VERSION ""

NS_ :

BS_:

BU_: XXX CAMERA FRONT_RADAR ADRV APRK

BO_ 53 ACCELERATOR: 32 XXX
 SG_ CHECKSUM : 0|16@1+ (1,0) [0|65535] "" XXX
 SG_ COUNTER : 16|8@1+ (1,0) [0|255] "" XXX
 SG_ GEAR : 192|3@1+ (1,0) [0|7] "" XXX
 SG_ ACCELERATOR_PEDAL : 40|8@1+ (1,0) [0|255] "" XXX

BO_ 64 GEAR_ALT: 32 XXX
 SG_ CHECKSUM : 0|16@1+ (1,0) [0|65535] "" XXX
 SG_ COUNTER : 16|8@1+ (1,0) [0|255] "" XXX
 SG_ GEAR : 32|3@1+ (1,0) [0|7] "" XXX

BO_ 69 GEAR: 24 XXX
 SG_ CHECKSUM : 0|16@1+ (1,0) [0|65535] "" XXX
 SG_ COUNTER : 16|8@1+ (1,0) [0|255] "" XXX
 SG_ GEAR : 44|3@1+ (1,0) [0|7] "" XXX

BO_ 80 LKAS: 16 XXX
 SG_ STEER_REQ : 52|1@1+ (1,0) [0|1] "" XXX
 SG_ TORQUE_REQUEST : 41|11@1+ (1,-1024) [0|4095] "" XXX
 SG_ LKA_ICON : 38|2@1+ (1,0) [0|255] "" XXX
 SG_ NEW_SIGNAL_1 : 27|2@1+ (1,0) [0|255] "" XXX
 SG_ LFA_BUTTON : 56|1@1+ (1,0) [0|255] "" XXX
 SG_ COUNTER : 16|8@1+ (1,0) [0|255] "" XXX
 SG_ CHECKSUM : 0|16@1+ (1,0) [0|65535] "" XXX
 SG_ STEER_MODE : 65|3@1+ (1,0) [0|1] "" XXX
 SG_ LKA_WARNING : 32|1@1+ (1,0) [0|1] "" XXX
 SG_ LKA_ASSIST : 62|1@1+ (1,0) [0|1] "" XXX
 SG_ LKA_MODE : 24|3@1+ (1,0) [0|7] "" XXX
 SG_ NEW_SIGNAL_2 : 70|2@0+ (1,0) [0|3] "" XXX
 SG_ HAS_LANE_SAFETY : 80|1@0+ (1,0) [0|1] "" XXX
 SG_ NEW_SIGNAL_3 : 111|8@0+ (1,0) [0|255] "" XXX
 SG_ FCA_SYSWARN : 40|1@0+ (1,0) [0|1] "" XXX

BO_ 81 ADRV_0x51: 32 ADRV
 SG_ COUNTER : 16|8@1+ (1,0) [0|255] "" XXX
 SG_ CHECKSUM : 0|16@1+ (1,0) [0|65535] "" XXX

BO_ 96 ESP_STATUS: 32 XXX
 SG_ CHECKSUM : 0|16@1+ (1,0) [0|65535] "" XXX
 SG_ COUNTER : 16|8@1+ (1,0) [0|255] "" XXX
 SG_ TRACTION_AND_STABILITY_CONTROL : 42|3@1+ (1,0) [0|63] "" XXX
 SG_ BRAKE_PRESSURE : 128|10@1+ (1,0) [0|65535] "" XXX
 SG_ BRAKE_PRESSED : 148|1@1+ (1,0) [0|3] "" XXX
 SG_ AUTO_HOLD : 192|1@0+ (1,0) [0|1] "" XXX

BO_ 101 BRAKE: 32 XXX
 SG_ CHECKSUM : 0|16@1+ (1,0) [0|65535] "" XXX
 SG_ COUNTER : 16|8@1+ (1,0) [0|255] "" XXX
 SG_ BRAKE_LIGHT : 29|1@0+ (1,0) [0|1] "" XXX
 SG_ BRAKE_POSITION : 40|16@1- (1,0) [0|65535] "" XXX
 SG_ BRAKE_PRESSED : 57|1@1+ (1,0) [0|3] "" XXX

BO_ 112 GEAR_ALT_2: 32 XXX
 SG_ CHECKSUM : 0|16@1+ (1,0) [0|65535] "" XXX
 SG_ COUNTER : 16|8@1+ (1,0) [0|255] "" XXX
 SG_ GEAR : 60|3@1+ (1,0) [0|7] "" XXX

BO_ 160 WHEEL_SPEEDS: 24 XXX
 SG_ CHECKSUM : 0|16@1+ (1,0) [0|65535] "" XXX
 SG_ COUNTER : 16|8@1+ (1,0) [0|255] "" XXX
 SG_ MOVING_FORWARD : 56|1@0+ (1,0) [0|1] "" XXX
 SG_ MOVING_BACKWARD : 57|1@0+ (1,0) [0|1] "" XXX
 SG_ MOVING_FORWARD2 : 58|1@0+ (1,0) [0|1] "" XXX
 SG_ MOVING_BACKWARD2 : 59|1@0+ (1,0) [0|1] "" XXX
 SG_ WHEEL_SPEED_1 : 64|16@1+ (0.03125,0) [0|65535] "kph" XXX
 SG_ WHEEL_SPEED_2 : 80|16@1+ (0.03125,0) [0|65535] "kph" XXX
 SG_ WHEEL_SPEED_3 : 96|16@1+ (0.03125,0) [0|65535] "kph" XXX
 SG_ WHEEL_SPEED_4 : 112|16@1+ (0.03125,0) [0|65535] "kph" XXX

BO_ 234 MDPS: 24 XXX
 SG_ CHECKSUM : 0|16@1+ (1,0) [0|65535] "" XXX
 SG_ COUNTER : 16|8@1+ (1,0) [0|255] "" XXX
 SG_ LKA_ACTIVE : 48|1@0+ (1,0) [0|16777215] "" XXX
 SG_ LKA_FAULT : 54|1@0+ (1,0) [0|1] "" XXX
 SG_ STEERING_OUT_TORQUE : 64|12@1+ (0.1,-204.8) [0|65535] "" XXX
 SG_ STEERING_COL_TORQUE : 80|13@1+ (1,-4095) [0|4095] "" XXX
 SG_ STEERING_ANGLE : 96|16@1- (-0.1,0) [0|255] "deg" XXX
 SG_ STEERING_ANGLE_2 : 128|16@1- (-0.1,0) [0|65535] "deg" XXX

BO_ 256 ACCELERATOR_BRAKE_ALT: 32 XXX
 SG_ CHECKSUM : 0|16@1+ (1,0) [0|65535] "" XXX
 SG_ COUNTER : 16|8@1+ (1,0) [0|255] "" XXX
 SG_ BRAKE_PRESSED : 32|1@1+ (1,0) [0|1] "" XXX
 SG_ ACCELERATOR_PEDAL_PRESSED : 176|1@1+ (1,0) [0|1] "" XXX

BO_ 261 ACCELERATOR_ALT: 32 XXX
 SG_ CHECKSUM : 0|16@1+ (1,0) [0|65535] "" XXX
 SG_ COUNTER : 16|8@1+ (1,0) [0|255] "" XXX
 SG_ ACCELERATOR_PEDAL : 103|10@1+ (0.25,0) [0|1022] "" XXX

BO_ 272 LKAS_ALT: 32 XXX
 SG_ STEER_REQ : 52|1@1+ (1,0) [0|1] "" XXX
 SG_ TORQUE_REQUEST : 41|11@1+ (1,-1024) [0|4095] "" XXX
 SG_ LKA_ICON : 38|2@1+ (1,0) [0|255] "" XXX
 SG_ NEW_SIGNAL_1 : 27|2@1+ (1,0) [0|255] "" XXX
 SG_ LFA_BUTTON : 56|1@1+ (1,0) [0|255] "" XXX
 SG_ COUNTER : 16|8@1+ (1,0) [0|255] "" XXX
 SG_ CHECKSUM : 0|16@1+ (1,0) [0|65535] "" XXX
 SG_ STEER_MODE : 65|3@1+ (1,0) [0|1] "" XXX
 SG_ LKA_WARNING : 32|1@1+ (1,0) [0|1] "" XXX
 SG_ LKA_ASSIST : 62|1@1+ (1,0) [0|1] "" XXX
 SG_ LKA_MODE : 24|3@1+ (1,0) [0|7] "" XXX
 SG_ NEW_SIGNAL_2 : 70|2@0+ (1,0) [0|3] "" XXX
 SG_ HAS_LANE_SAFETY : 80|1@0+ (1,0) [0|1] "" XXX
 SG_ NEW_SIGNAL_3 : 111|8@0+ (1,0) [0|255] "" XXX
 SG_ FCA_SYSWARN : 40|1@0+ (1,0) [0|1] "" XXX

BO_ 293 STEERING_SENSORS: 16 XXX
 SG_ CHECKSUM : 0|16@1+ (1,0) [0|65535] "" XXX
 SG_ COUNTER : 16|8@1+ (1,0) [0|255] "" XXX
 SG_ STEERING_RATE : 40|8@1+ (4,0) [0|1016] "deg/s" XXX
 SG_ STEERING_ANGLE : 24|16@1- (-0.1,0) [0|255] "deg" XXX

BO_ 298 LFA: 16 ADRV
 SG_ STEER_REQ : 52|1@1+ (1,0) [0|1] "" XXX
 SG_ TORQUE_REQUEST : 41|11@1+ (1,-1024) [0|4095] "" XXX
 SG_ LKA_ICON : 38|2@1+ (1,0) [0|255] "" XXX
 SG_ NEW_SIGNAL_1 : 27|2@1+ (1,0) [0|255] "" XXX
 SG_ LFA_BUTTON : 56|1@1+ (1,0) [0|255] "" XXX
 SG_ COUNTER : 16|8@1+ (1,0) [0|255] "" XXX
 SG_ CHECKSUM : 0|16@1+ (1,0) [0|65535] "" XXX
 SG_ STEER_MODE : 65|3@1+ (1,0) [0|1] "" XXX
 SG_ LKA_WARNING : 32|1@1+ (1,0) [0|1] "" XXX
 SG_ LKA_ASSIST : 62|1@1+ (1,0) [0|1] "" XXX
 SG_ LKA_MODE : 24|3@1+ (1,0) [0|7] "" XXX
 SG_ NEW_SIGNAL_2 : 70|2@0+ (1,0) [0|3] "" XXX
 SG_ HAS_LANE_SAFETY : 80|1@0+ (1,0) [0|1] "" XXX
 SG_ NEW_SIGNAL_3 : 111|8@0+ (1,0) [0|255] "" XXX

BO_ 304 GEAR_SHIFTER: 16 XXX
 SG_ CHECKSUM : 0|16@1+ (1,0) [0|65535] "" XXX
 SG_ COUNTER : 16|8@1+ (1,0) [0|255] "" XXX
 SG_ PARK_BUTTON : 32|2@1+ (1,0) [0|3] "" XXX
 SG_ GEAR : 64|3@1+ (1,0) [0|7] "" XXX
 SG_ KNOB_POSITION : 40|3@1+ (1,0) [0|3] "" XXX

BO_ 357 SPAS1: 24 APRK
 SG_ CHECKSUM : 0|16@1+ (1,0) [0|65535] "" XXX
 SG_ COUNTER : 16|8@1+ (1,0) [0|0] "" XXX
 SG_ NEW_SIGNAL_1 : 96|16@1- (0.1,0) [0|0] "" XXX
 SG_ NEW_SIGNAL_2 : 90|3@1+ (1,0) [0|0] "" XXX

BO_ 362 SPAS2: 32 APRK
 SG_ CHECKSUM : 0|16@1+ (1,0) [0|65535] "" XXX
 SG_ COUNTER : 16|8@1+ (1,0) [0|0] "" XXX
 SG_ BLINKER_CONTROL : 133|3@1+ (1,0) [0|0] "" XXX

BO_ 373 TCS: 24 XXX
 SG_ CHECKSUM : 0|16@1+ (1,0) [0|65535] "" XXX
 SG_ COUNTER : 16|8@1+ (1,0) [0|255] "" XXX
 SG_ NEW_SIGNAL_1 : 80|1@0+ (1,0) [0|1] "" XXX
 SG_ NEW_SIGNAL_2 : 74|1@0+ (1,0) [0|1] "" XXX
 SG_ BRAKE_LIGHT : 76|1@0+ (1,0) [0|1] "" XXX
 SG_ NEW_SIGNAL_4 : 24|7@1+ (1,0) [0|127] "" XXX
 SG_ aBasis : 32|11@1+ (0.01,-10.23) [0|7] "m/s^2" XXX
 SG_ NEW_SIGNAL_5 : 72|1@0+ (1,0) [0|1] "" XXX
 SG_ NEW_SIGNAL_6 : 128|4@1+ (1,0) [0|15] "" XXX
 SG_ NEW_SIGNAL_7 : 135|2@0+ (1,0) [0|3] "" XXX
 SG_ PROBABLY_EQUIP : 136|2@1+ (1,0) [0|3] "" XXX
 SG_ AEB_EQUIP_MAYBE : 96|1@0+ (1,0) [0|1] "" XXX
 SG_ EQUIP_MAYBE : 64|1@0+ (1,0) [0|1] "" XXX
 SG_ DriverBraking : 81|1@0+ (1,0) [0|1] "" XXX
 SG_ DriverBrakingLowSens : 84|1@1+ (1,0) [0|1] "" XXX
 SG_ ACC_REQ : 68|1@0+ (1,0) [0|1] "" XXX
 SG_ ACCEL_REF_ACC : 48|11@1- (1,0) [0|1023] "" XXX
 SG_ ACCEnable : 67|2@0+ (1,0) [0|3] "" XXX

BO_ 352 ADRV_0x160: 16 ADRV
 SG_ CHECKSUM : 0|16@1+ (1,0) [0|65535] "" XXX
 SG_ COUNTER : 16|8@1+ (1,0) [0|255] "" XXX
 SG_ SET_ME_FF : 64|8@1+ (1,0) [0|255] "" XXX
 SG_ SET_ME_FC : 72|8@1+ (1,0) [0|255] "" XXX
 SG_ SET_ME_2 : 56|8@1+ (1,0) [0|1] "" XXX
 SG_ AEB_SETTING : 24|2@1+ (1,0) [0|255] "" XXX
 SG_ SET_ME_9 : 80|8@1+ (1,0) [0|255] "" XXX

BO_ 384 CAM_0x180: 32 CAMERA
 SG_ CHECKSUM : 0|16@1+ (1,0) [0|65535] "" XXX
 SG_ COUNTER : 16|8@1+ (1,0) [0|255] "" XXX

BO_ 385 CAM_0x181: 32 CAMERA
 SG_ CHECKSUM : 0|16@1+ (1,0) [0|65535] "" XXX
 SG_ COUNTER : 16|8@1+ (1,0) [0|255] "" XXX

BO_ 386 CAM_0x182: 32 CAMERA
 SG_ CHECKSUM : 0|16@1+ (1,0) [0|65535] "" XXX
 SG_ COUNTER : 16|8@1+ (1,0) [0|255] "" XXX

BO_ 387 CAM_0x183: 32 CAMERA
 SG_ CHECKSUM : 0|16@1+ (1,0) [0|65535] "" XXX
 SG_ COUNTER : 16|8@1+ (1,0) [0|255] "" XXX

BO_ 388 CAM_0x184: 32 CAMERA
 SG_ CHECKSUM : 0|16@1+ (1,0) [0|65535] "" XXX
 SG_ COUNTER : 16|8@1+ (1,0) [0|255] "" XXX

BO_ 389 CAM_0x185: 8 CAMERA
 SG_ CHECKSUM : 0|16@1+ (1,0) [0|65535] "" XXX
 SG_ COUNTER : 16|8@1+ (1,0) [0|255] "" XXX

BO_ 416 SCC_CONTROL: 32 ADRV
 SG_ CHECKSUM : 0|16@1+ (1,0) [0|65535] "" XXX
 SG_ NEW_SIGNAL_1 : 64|2@1+ (1,0) [0|3] "" XXX
 SG_ NEW_SIGNAL_8 : 170|4@1+ (1,0) [0|15] "" XXX
 SG_ ZEROS : 215|48@0+ (1,0) [0|281474976710655] "" XXX
 SG_ ZEROS_3 : 191|7@0+ (1,0) [0|127] "" XXX
 SG_ ZEROS_4 : 183|4@0+ (1,0) [0|63] "" XXX
 SG_ ZEROS_6 : 119|16@0+ (1,0) [0|65535] "" XXX
 SG_ ZEROS_8 : 95|5@0+ (1,0) [0|31] "" XXX
 SG_ NEW_SIGNAL_3 : 109|2@0+ (1,0) [0|1] "" XXX
 SG_ SET_ME_TMP_64 : 55|8@0+ (1,0) [0|63] "" XXX
 SG_ SET_ME_2 : 105|3@1+ (1,0) [0|7] "" XXX
 SG_ NEW_SIGNAL_6 : 104|1@0+ (1,0) [0|1] "" XXX
 SG_ COUNTER : 16|8@1+ (1,0) [0|255] "" XXX
 SG_ ZEROS_9 : 71|5@1+ (1,0) [0|15] "" XXX
 SG_ ZEROS_10 : 111|2@0+ (1,0) [0|3] "" XXX
 SG_ ObjValid : 46|1@0+ (1,0) [0|3] "" XXX
 SG_ NEW_SIGNAL_2 : 168|2@1+ (1,0) [0|3] "" XXX
 SG_ OBJ_STATUS : 176|3@1+ (1,0) [0|7] "" XXX
 SG_ ACC_ObjDist : 24|11@1+ (0.1,0) [0|204.7] "m" XXX
 SG_ ZEROS_5 : 77|11@1+ (1,0) [0|2047] "" XXX
 SG_ DISTANCE_SETTING : 88|3@1+ (1,0) [0|3] "" XXX
 SG_ ZEROS_2 : 207|5@0+ (1,0) [0|63] "" XXX
 SG_ CRUISE_STANDSTILL : 76|1@1+ (1,0) [0|1] "" XXX
 SG_ aReqRaw : 140|11@1+ (0.01,-10.23) [-10.23|10.24] "m/s^2" XXX
 SG_ aReqValue : 128|11@1+ (0.01,-10.23) [-10.23|10.24] "m/s^2" XXX
 SG_ ZEROS_7 : 63|8@0+ (1,0) [0|255] "" XXX
 SG_ ACCMode : 68|3@1+ (1,0) [0|7] "" XXX
 SG_ ACC_ObjRelSpd : 35|11@1+ (0.1,-170) [-170|187.7] "m/s" XXX
 SG_ JerkLowerLimit : 166|7@0+ (0.1,0) [0|12.7] "m/s^3" XXX
 SG_ StopReq : 184|1@0+ (1,0) [0|1] "" XXX
 SG_ NEW_SIGNAL_15 : 192|11@1+ (0.1,0) [0|204.7] "m" XXX
 SG_ VSetDis : 103|8@0+ (1,0) [0|255] "km/h or mph" XXX
 SG_ MainMode_ACC : 66|1@1+ (1,0) [0|1] "" XXX
 SG_ JerkUpperLimit : 158|7@0+ (0.1,0) [0|0] "" XXX

BO_ 426 CRUISE_BUTTONS_ALT: 16 XXX
 SG_ CHECKSUM : 0|16@1+ (1,0) [0|65535] "" XXX
 SG_ COUNTER : 16|8@1+ (1,0) [0|255] "" XXX
 SG_ NEW_SIGNAL_1 : 24|4@1+ (1,0) [0|15] "" XXX
 SG_ SET_ME_1 : 28|2@1+ (1,0) [0|3] "" XXX
 SG_ DISTANCE_UNIT : 30|1@1+ (1,0) [0|1] "" XXX
 SG_ NEW_SIGNAL_2 : 31|3@1+ (1,0) [0|7] "" XXX
 SG_ ADAPTIVE_CRUISE_MAIN_BTN : 34|1@1+ (1,0) [0|1] "" XXX
 SG_ NEW_SIGNAL_3 : 35|1@1+ (1,0) [0|1] "" XXX
 SG_ LFA_BTN : 39|1@1+ (1,0) [0|1] "" XXX
 SG_ CRUISE_BUTTONS : 36|3@1+ (1,0) [0|4] "" XXX
 SG_ NEW_SIGNAL_4 : 40|1@1+ (1,0) [0|1] "" XXX
 SG_ NORMAL_CRUISE_MAIN_BTN : 41|1@1+ (1,0) [0|1] "" XXX
 SG_ NEW_SIGNAL_5 : 42|2@1+ (1,0) [0|3] "" XXX
 SG_ SET_ME_2 : 44|3@1+ (1,0) [0|7] "" XXX
 SG_ NEW_SIGNAL_6 : 47|1@1+ (1,0) [0|1] "" XXX
 SG_ BYTE6 : 48|8@1+ (1,0) [0|255] "" XXX
 SG_ BYTE7 : 56|8@1+ (1,0) [0|255] "" XXX
 SG_ BYTE8 : 64|8@1+ (1,0) [0|255] "" XXX
 SG_ BYTE9 : 72|8@1+ (1,0) [0|255] "" XXX
 SG_ BYTE10 : 80|8@1+ (1,0) [0|255] "" XXX
 SG_ BYTE11 : 88|8@1+ (1,0) [0|255] "" XXX
 SG_ BYTE12 : 96|8@1+ (1,0) [0|255] "" XXX
 SG_ BYTE13 : 104|8@1+ (1,0) [0|255] "" XXX
 SG_ BYTE14 : 112|8@1+ (1,0) [0|255] "" XXX
 SG_ BYTE15 : 120|8@1+ (1,0) [0|255] "" XXX

BO_ 438 CAM_0x1b6: 32 CAMERA
 SG_ CHECKSUM : 0|16@1+ (1,0) [0|65535] "" XXX
 SG_ COUNTER : 16|8@1+ (1,0) [0|255] "" XXX

BO_ 439 CAM_0x1b7: 32 CAMERA
 SG_ CHECKSUM : 0|16@1+ (1,0) [0|65535] "" XXX
 SG_ COUNTER : 16|8@1+ (1,0) [0|255] "" XXX

BO_ 440 CAM_0x1b8: 32 CAMERA
 SG_ CHECKSUM : 0|16@1+ (1,0) [0|65535] "" XXX
 SG_ COUNTER : 16|8@1+ (1,0) [0|255] "" XXX

BO_ 441 CAM_0x1b9: 32 CAMERA
 SG_ CHECKSUM : 0|16@1+ (1,0) [0|65535] "" XXX
 SG_ COUNTER : 16|8@1+ (1,0) [0|255] "" XXX

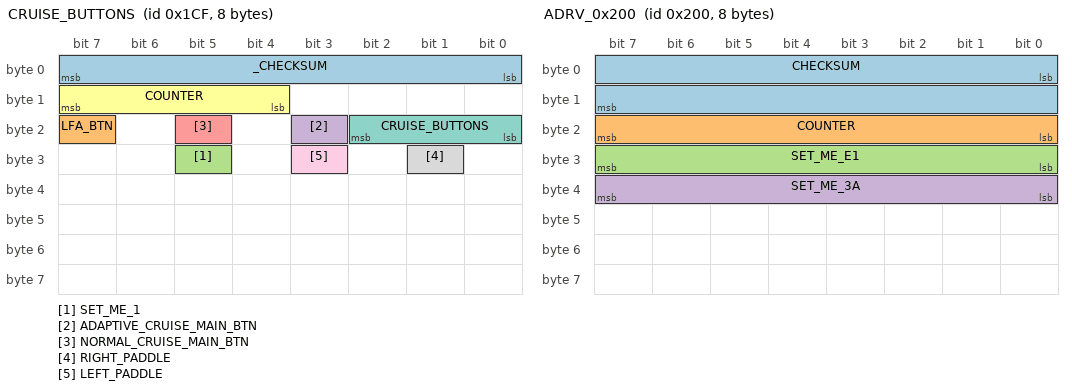
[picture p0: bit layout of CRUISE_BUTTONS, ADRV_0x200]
BO_ 463 CRUISE_BUTTONS: 8 XXX
 SG_ _CHECKSUM : 0|8@1+ (1,0) [0|65535] "" XXX
 SG_ LFA_BTN : 23|1@1+ (1,0) [0|1] "" XXX
 SG_ SET_ME_1 : 29|1@1+ (1,0) [0|1] "" XXX
 SG_ ADAPTIVE_CRUISE_MAIN_BTN : 19|1@1+ (1,0) [0|1] "" XXX
 SG_ NORMAL_CRUISE_MAIN_BTN : 21|1@1+ (1,0) [0|1] "" XXX
 SG_ COUNTER : 12|4@1+ (1,0) [0|255] "" XXX
 SG_ CRUISE_BUTTONS : 16|3@1+ (1,0) [0|3] "" XXX
 SG_ RIGHT_PADDLE : 25|1@1+ (1,0) [0|1] "" XXX
 SG_ LEFT_PADDLE : 27|1@1+ (1,0) [0|1] "" XXX

BO_ 474 ADRV_0x1da: 32 ADRV
 SG_ CHECKSUM : 0|16@1+ (1,0) [0|65535] "" XXX
 SG_ COUNTER : 16|8@1+ (1,0) [0|255] "" XXX
 SG_ SET_ME_22 : 31|8@0+ (1,0) [0|255] "" XXX
 SG_ SET_ME_41 : 47|8@0+ (1,0) [0|255] "" XXX

BO_ 480 LFAHDA_CLUSTER: 16 ADRV
 SG_ CHECKSUM : 0|16@1+ (1,0) [0|65535] "" XXX
 SG_ COUNTER : 16|8@1+ (1,0) [0|255] "" XXX
 SG_ HDA_ICON : 31|1@1+ (1,0) [0|1] "" XXX
 SG_ LFA_ICON : 47|2@1+ (1,0) [0|3] "" XXX
 SG_ NEW_SIGNAL_1 : 32|3@1+ (1,0) [0|7] "" XXX
 SG_ NEW_SIGNAL_2 : 30|1@0+ (1,0) [0|1] "" XXX
 SG_ NEW_SIGNAL_3 : 49|1@0+ (1,0) [0|1] "" XXX
 SG_ NEW_SIGNAL_4 : 24|1@0+ (1,0) [0|1] "" XXX

BO_ 490 ADRV_0x1ea: 32 ADRV
 SG_ CHECKSUM : 0|16@1+ (1,0) [0|65535] "" XXX
 SG_ COUNTER : 16|8@1+ (1,0) [0|255] "" XXX
 SG_ SET_ME_1C : 31|8@0+ (1,0) [0|255] "" XXX
 SG_ NEW_SIGNAL_1 : 32|2@1+ (1,0) [0|3] "" XXX
 SG_ NEW_SIGNAL_2 : 47|2@0+ (1,0) [0|3] "" XXX
 SG_ NEW_SIGNAL_3 : 55|8@0+ (1,0) [0|255] "" XXX
 SG_ NEW_SIGNAL_4 : 64|6@1+ (1,0) [0|31] "" XXX
 SG_ NEW_SIGNAL_5 : 72|2@1+ (1,0) [0|3] "" XXX
 SG_ NEW_SIGNAL_6 : 75|5@1+ (1,0) [0|31] "" XXX
 SG_ NEW_SIGNAL_7 : 80|5@1+ (1,0) [0|31] "" XXX
 SG_ NEW_SIGNAL_8 : 88|7@1+ (1,0) [0|127] "" XXX
 SG_ NEW_SIGNAL_9 : 96|1@0+ (1,0) [0|1] "" XXX
 SG_ NEW_SIGNAL_10 : 143|5@0+ (1,0) [0|31] "" XXX
 SG_ NEW_SIGNAL_11 : 144|3@1+ (1,0) [0|7] "" XXX
 SG_ NEW_SIGNAL_12 : 152|6@1+ (1,0) [0|63] "" XXX
 SG_ NEW_SIGNAL_13 : 160|1@0+ (1,0) [0|1] "" XXX
 SG_ NEW_SIGNAL_14 : 163|5@1+ (1,0) [0|31] "" XXX
 SG_ NEW_SIGNAL_15 : 175|4@0+ (1,0) [0|63] "" XXX
 SG_ NEW_SIGNAL_16 : 168|3@1+ (1,0) [0|7] "" XXX
 SG_ NEW_SIGNAL_17 : 176|2@1+ (1,0) [0|3] "" XXX
 SG_ NEW_SIGNAL_18 : 184|1@0+ (1,0) [0|1] "" XXX
 SG_ NEW_SIGNAL_19 : 208|3@1+ (1,0) [0|7] "" XXX
 SG_ NEW_SIGNAL_20 : 212|1@0+ (1,0) [0|1] "" XXX
 SG_ SET_ME_FF : 120|8@1+ (1,0) [0|255] "" XXX
 SG_ SET_ME_TMP_F : 232|5@1+ (1,0) [0|31] "" XXX
 SG_ SET_ME_TMP_F_2 : 240|5@1+ (1,0) [0|31] "" XXX

BO_ 507 CAM_0x1fb: 32 CAMERA
 SG_ CHECKSUM : 0|16@1+ (1,0) [0|65535] "" XXX
 SG_ COUNTER : 16|8@1+ (1,0) [0|255] "" XXX

BO_ 512 ADRV_0x200: 8 ADRV
 SG_ CHECKSUM : 0|16@1+ (1,0) [0|65535] "" XXX
 SG_ COUNTER : 16|8@1+ (1,0) [0|255] "" XXX
 SG_ SET_ME_E1 : 24|8@1+ (1,0) [0|255] "" XXX
 SG_ SET_ME_3A : 32|8@1+ (1,0) [0|255] "" XXX

BO_ 513 RADAR_0x201: 32 FRONT_RADAR
 SG_ CHECKSUM : 0|16@1+ (1,0) [0|65535] "" XXX
 SG_ COUNTER : 16|8@1+ (1,0) [0|255] "" XXX

BO_ 528 RADAR_0x210: 32 FRONT_RADAR
 SG_ CHECKSUM : 0|16@1+ (1,0) [0|65535] "" XXX
 SG_ COUNTER : 16|8@1+ (1,0) [0|255] "" XXX

BO_ 529 RADAR_0x211: 32 FRONT_RADAR
 SG_ CHECKSUM : 0|16@1+ (1,0) [0|65535] "" XXX
 SG_ COUNTER : 16|8@1+ (1,0) [0|255] "" XXX

BO_ 530 RADAR_0x212: 32 FRONT_RADAR
 SG_ CHECKSUM : 0|16@1+ (1,0) [0|65535] "" XXX
 SG_ COUNTER : 16|8@1+ (1,0) [0|255] "" XXX

BO_ 531 RADAR_0x213: 32 FRONT_RADAR
 SG_ CHECKSUM : 0|16@1+ (1,0) [0|65535] "" XXX
 SG_ COUNTER : 16|8@1+ (1,0) [0|255] "" XXX

BO_ 532 RADAR_0x214: 32 FRONT_RADAR
 SG_ CHECKSUM : 0|16@1+ (1,0) [0|65535] "" XXX
 SG_ COUNTER : 16|8@1+ (1,0) [0|255] "" XXX

BO_ 533 RADAR_0x215: 32 FRONT_RADAR
 SG_ CHECKSUM : 0|16@1+ (1,0) [0|65535] "" XXX
 SG_ COUNTER : 16|8@1+ (1,0) [0|255] "" XXX

BO_ 534 RADAR_0x216: 32 FRONT_RADAR
 SG_ CHECKSUM : 0|16@1+ (1,0) [0|65535] "" XXX
 SG_ COUNTER : 16|8@1+ (1,0) [0|255] "" XXX

BO_ 535 RADAR_0x217: 32 FRONT_RADAR
 SG_ CHECKSUM : 0|16@1+ (1,0) [0|65535] "" XXX
 SG_ COUNTER : 16|8@1+ (1,0) [0|255] "" XXX

BO_ 536 RADAR_0x218: 32 FRONT_RADAR
 SG_ CHECKSUM : 0|16@1+ (1,0) [0|65535] "" XXX
 SG_ COUNTER : 16|8@1+ (1,0) [0|255] "" XXX

BO_ 537 RADAR_0x219: 32 FRONT_RADAR
 SG_ CHECKSUM : 0|16@1+ (1,0) [0|65535] "" XXX
 SG_ COUNTER : 16|8@1+ (1,0) [0|255] "" XXX

BO_ 538 RADAR_0x21a: 32 FRONT_RADAR
 SG_ CHECKSUM : 0|16@1+ (1,0) [0|65535] "" XXX
 SG_ COUNTER : 16|8@1+ (1,0) [0|255] "" XXX

BO_ 539 RADAR_0x21b: 32 FRONT_RADAR
 SG_ CHECKSUM : 0|16@1+ (1,0) [0|65535] "" XXX
 SG_ COUNTER : 16|8@1+ (1,0) [0|255] "" XXX

BO_ 540 RADAR_0x21c: 32 FRONT_RADAR
 SG_ CHECKSUM : 0|16@1+ (1,0) [0|65535] "" XXX
 SG_ COUNTER : 16|8@1+ (1,0) [0|255] "" XXX

BO_ 541 RADAR_0x21d: 32 FRONT_RADAR
 SG_ CHECKSUM : 0|16@1+ (1,0) [0|65535] "" XXX
 SG_ COUNTER : 16|8@1+ (1,0) [0|255] "" XXX

BO_ 542 RADAR_0x21e: 32 FRONT_RADAR
 SG_ CHECKSUM : 0|16@1+ (1,0) [0|65535] "" XXX
 SG_ COUNTER : 16|8@1+ (1,0) [0|255] "" XXX

BO_ 543 RADAR_0x21f: 32 FRONT_RADAR
 SG_ CHECKSUM : 0|16@1+ (1,0) [0|65535] "" XXX
 SG_ COUNTER : 16|8@1+ (1,0) [0|255] "" XXX

BO_ 576 RADAR_0x240: 16 FRONT_RADAR
 SG_ CHECKSUM : 0|16@1+ (1,0) [0|65535] "" XXX
 SG_ COUNTER : 16|8@1+ (1,0) [0|255] "" XXX

BO_ 593 RADAR_0x251: 16 FRONT_RADAR
 SG_ CHECKSUM : 0|16@1+ (1,0) [0|65535] "" XXX
 SG_ COUNTER : 16|8@1+ (1,0) [0|255] "" XXX

BO_ 674 CAM_0x2a2: 32 CAMERA
 SG_ CHECKSUM : 0|16@1+ (1,0) [0|65535] "" XXX
 SG_ COUNTER : 16|8@1+ (1,0) [0|255] "" XXX

BO_ 675 CAM_0x2a3: 32 CAMERA
 SG_ CHECKSUM : 0|16@1+ (1,0) [0|65535] "" XXX
 SG_ COUNTER : 16|8@1+ (1,0) [0|255] "" XXX

BO_ 676 CAM_0x2a4: 24 XXX
 SG_ CHECKSUM : 0|16@1+ (1,0) [0|65535] "" XXX
 SG_ COUNTER : 16|8@1+ (1,0) [0|255] "" XXX
 SG_ BYTE3 : 24|8@1+ (1,0) [0|255] "" XXX
 SG_ BYTE4 : 32|8@1+ (1,0) [0|255] "" XXX
 SG_ BYTE5 : 40|8@1+ (1,0) [0|255] "" XXX
 SG_ BYTE6 : 48|8@1+ (1,0) [0|255] "" XXX
 SG_ LEFT_LANE_LINE : 56|2@1+ (1,0) [0|3] "" XXX
 SG_ SET_ME_0 : 58|2@1+ (1,0) [0|3] "" XXX
 SG_ RIGHT_LANE_LINE : 60|2@1+ (1,0) [0|3] "" XXX
 SG_ SET_ME_0_2 : 62|2@1+ (1,0) [0|3] "" XXX
 SG_ BYTE8 : 64|8@1+ (1,0) [0|255] "" XXX
 SG_ BYTE9 : 72|8@1+ (1,0) [0|255] "" XXX
 SG_ BYTE10 : 80|8@1+ (1,0) [0|255] "" XXX
 SG_ BYTE11 : 88|8@1+ (1,0) [0|255] "" XXX
 SG_ BYTE12 : 96|8@1+ (1,0) [0|255] "" XXX
 SG_ BYTE13 : 104|8@1+ (1,0) [0|255] "" XXX
 SG_ BYTE14 : 112|8@1+ (1,0) [0|255] "" XXX
 SG_ BYTE15 : 120|8@1+ (1,0) [0|255] "" XXX
 SG_ BYTE16 : 128|8@1+ (1,0) [0|255] "" XXX
 SG_ BYTE17 : 136|8@1+ (1,0) [0|255] "" XXX
 SG_ BYTE18 : 144|8@1+ (1,0) [0|255] "" XXX
 SG_ BYTE19 : 152|8@1+ (1,0) [0|255] "" XXX
 SG_ BYTE20 : 160|8@1+ (1,0) [0|255] "" XXX
 SG_ BYTE21 : 168|8@1+ (1,0) [0|255] "" XXX
 SG_ BYTE22 : 176|8@1+ (1,0) [0|255] "" XXX
 SG_ BYTE23 : 184|8@1+ (1,0) [0|255] "" XXX

BO_ 699 CAM_0x2bb: 32 CAMERA
 SG_ CHECKSUM : 0|16@1+ (1,0) [0|65535] "" XXX
 SG_ COUNTER : 16|8@1+ (1,0) [0|255] "" XXX

BO_ 700 CAM_0x2bc: 32 CAMERA
 SG_ CHECKSUM : 0|16@1+ (1,0) [0|65535] "" XXX
 SG_ COUNTER : 16|8@1+ (1,0) [0|255] "" XXX

BO_ 701 CAM_0x2bd: 32 CAMERA
 SG_ CHECKSUM : 0|16@1+ (1,0) [0|65535] "" XXX
 SG_ COUNTER : 16|8@1+ (1,0) [0|255] "" XXX

BO_ 702 CAM_0x2be: 32 CAMERA
 SG_ CHECKSUM : 0|16@1+ (1,0) [0|65535] "" XXX
 SG_ COUNTER : 16|8@1+ (1,0) [0|255] "" XXX

BO_ 736 MANUAL_SPEED_LIMIT_ASSIST: 32 XXX
 SG_ CHECKSUM : 0|16@1+ (1,0) [0|65535] "" XXX
 SG_ COUNTER : 16|8@1+ (1,0) [0|255] "" XXX
 SG_ MSLA_STATUS : 26|2@1+ (1,0) [0|3] "" XXX
 SG_ MSLA_ENABLED : 38|1@1+ (1,0) [0|1] "" XXX
 SG_ MAX_SPEED : 55|8@0+ (1,0) [0|255] "" XXX
 SG_ MAX_SPEED_COPY : 144|8@1+ (1,0) [0|255] "" XXX

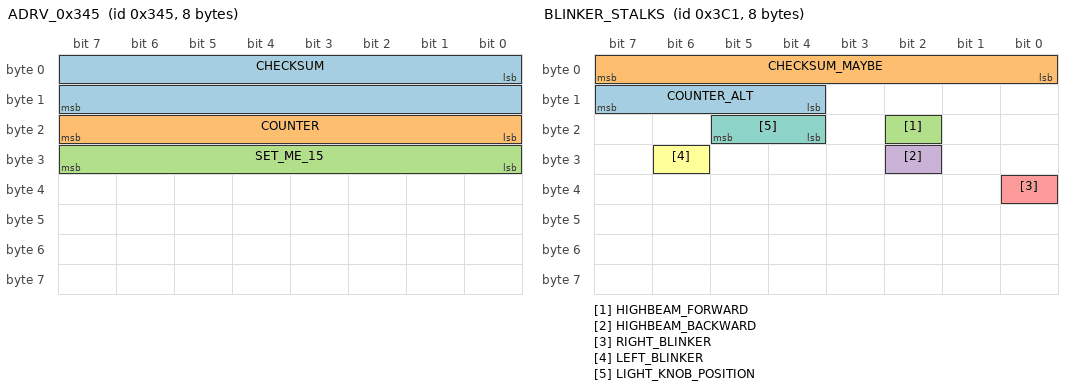
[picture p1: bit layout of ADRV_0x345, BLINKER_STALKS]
BO_ 837 ADRV_0x345: 8 ADRV
 SG_ CHECKSUM : 0|16@1+ (1,0) [0|65535] "" XXX
 SG_ COUNTER : 16|8@1+ (1,0) [0|255] "" XXX
 SG_ SET_ME_15 : 24|8@1+ (1,0) [0|255] "" XXX

BO_ 866 CAM_0x362: 32 CAMERA
 SG_ CHECKSUM : 0|16@1+ (1,0) [0|65535] "" XXX
 SG_ COUNTER : 16|8@1+ (1,0) [0|255] "" XXX
 SG_ BYTE3 : 24|8@1+ (1,0) [0|255] "" XXX
 SG_ BYTE4 : 32|8@1+ (1,0) [0|255] "" XXX
 SG_ BYTE5 : 40|8@1+ (1,0) [0|255] "" XXX
 SG_ BYTE6 : 48|8@1+ (1,0) [0|255] "" XXX
 SG_ LEFT_LANE_LINE : 56|2@1+ (1,0) [0|3] "" XXX
 SG_ SET_ME_0 : 58|2@1+ (1,0) [0|3] "" XXX
 SG_ RIGHT_LANE_LINE : 60|2@1+ (1,0) [0|3] "" XXX
 SG_ SET_ME_0_2 : 62|2@1+ (1,0) [0|3] "" XXX
 SG_ BYTE8 : 64|8@1+ (1,0) [0|255] "" XXX
 SG_ BYTE9 : 72|8@1+ (1,0) [0|255] "" XXX
 SG_ BYTE10 : 80|8@1+ (1,0) [0|255] "" XXX
 SG_ BYTE11 : 88|8@1+ (1,0) [0|255] "" XXX
 SG_ BYTE12 : 96|8@1+ (1,0) [0|255] "" XXX
 SG_ BYTE13 : 104|8@1+ (1,0) [0|255] "" XXX
 SG_ BYTE14 : 112|8@1+ (1,0) [0|255] "" XXX
 SG_ BYTE15 : 120|8@1+ (1,0) [0|255] "" XXX
 SG_ BYTE16 : 128|8@1+ (1,0) [0|255] "" XXX
 SG_ BYTE17 : 136|8@1+ (1,0) [0|255] "" XXX
 SG_ BYTE18 : 144|8@1+ (1,0) [0|255] "" XXX
 SG_ BYTE19 : 152|8@1+ (1,0) [0|255] "" XXX
 SG_ BYTE20 : 160|8@1+ (1,0) [0|255] "" XXX
 SG_ BYTE21 : 168|8@1+ (1,0) [0|255] "" XXX
 SG_ BYTE22 : 176|8@1+ (1,0) [0|255] "" XXX
 SG_ BYTE23 : 184|8@1+ (1,0) [0|255] "" XXX
 SG_ BYTE24 : 192|8@1+ (1,0) [0|255] "" XXX
 SG_ BYTE25 : 200|8@1+ (1,0) [0|255] "" XXX
 SG_ BYTE26 : 208|8@1+ (1,0) [0|255] "" XXX
 SG_ BYTE27 : 216|8@1+ (1,0) [0|255] "" XXX
 SG_ BYTE28 : 224|8@1+ (1,0) [0|255] "" XXX
 SG_ BYTE29 : 232|8@1+ (1,0) [0|255] "" XXX
 SG_ BYTE30 : 240|8@1+ (1,0) [0|255] "" XXX
 SG_ BYTE31 : 248|8@1+ (1,0) [0|255] "" XXX

BO_ 961 BLINKER_STALKS: 8 XXX
 SG_ COUNTER_ALT : 15|4@0+ (1,0) [0|15] "" XXX
 SG_ CHECKSUM_MAYBE : 7|8@0+ (1,0) [0|255] "" XXX
 SG_ HIGHBEAM_FORWARD : 18|1@0+ (1,0) [0|1] "" XXX
 SG_ HIGHBEAM_BACKWARD : 26|1@0+ (1,0) [0|1] "" XXX
 SG_ RIGHT_BLINKER : 32|1@0+ (1,0) [0|1] "" XXX
 SG_ LEFT_BLINKER : 30|1@0+ (1,0) [0|1] "" XXX
 SG_ LIGHT_KNOB_POSITION : 21|2@0+ (1,0) [0|3] "" XXX

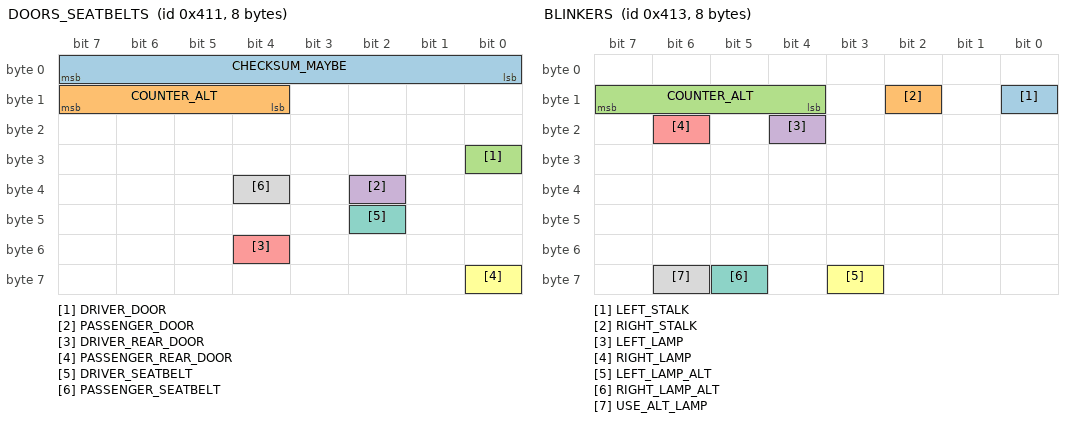
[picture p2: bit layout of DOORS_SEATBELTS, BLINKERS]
BO_ 1041 DOORS_SEATBELTS: 8 XXX
 SG_ CHECKSUM_MAYBE : 7|8@0+ (1,0) [0|65535] "" XXX
 SG_ COUNTER_ALT : 15|4@0+ (1,0) [0|15] "" XXX
 SG_ DRIVER_DOOR : 24|1@1+ (1,0) [0|1] "" XXX
 SG_ PASSENGER_DOOR : 34|1@0+ (1,0) [0|1] "" XXX
 SG_ DRIVER_REAR_DOOR : 52|1@0+ (1,0) [0|1] "" XXX
 SG_ PASSENGER_REAR_DOOR : 56|1@0+ (1,0) [0|1] "" XXX
 SG_ DRIVER_SEATBELT : 42|1@0+ (1,0) [0|1] "" XXX
 SG_ PASSENGER_SEATBELT : 36|1@0+ (1,0) [0|1] "" XXX

BO_ 1043 BLINKERS: 8 XXX
 SG_ LEFT_STALK : 8|1@0+ (1,0) [0|1] "" XXX
 SG_ RIGHT_STALK : 10|1@0+ (1,0) [0|1] "" XXX
 SG_ COUNTER_ALT : 15|4@0+ (1,0) [0|15] "" XXX
 SG_ LEFT_LAMP : 20|1@0+ (1,0) [0|1] "" XXX
 SG_ RIGHT_LAMP : 22|1@0+ (1,0) [0|1] "" XXX
 SG_ LEFT_LAMP_ALT : 59|1@0+ (1,0) [0|1] "" XXX
 SG_ RIGHT_LAMP_ALT : 61|1@0+ (1,0) [0|1] "" XXX
 SG_ USE_ALT_LAMP : 62|1@0+ (1,0) [0|1] "" XXX

BO_ 1240 CLUSTER_INFO: 8 XXX
 SG_ DISTANCE_UNIT : 0|1@1+ (1,0) [0|1] "" XXX

BO_ 442 BLINDSPOTS_REAR_CORNERS: 24 XXX
 SG_ COUNTER : 16|8@1+ (1,0) [0|255] "" XXX
 SG_ CHECKSUM : 0|16@1+ (1,0) [0|65535] "" XXX
 SG_ NEW_SIGNAL_2 : 96|1@0+ (1,0) [0|1] "" XXX
 SG_ COLLISION_AVOIDANCE_ACTIVE : 68|1@0+ (1,0) [0|1] "" XXX
 SG_ LEFT_MB : 30|1@0+ (1,0) [0|3] "" XXX
 SG_ LEFT_BLOCKED : 24|1@0+ (1,0) [0|1] "" XXX
 SG_ MORE_LEFT_PROB : 32|1@1+ (1,0) [0|3] "" XXX
 SG_ FL_INDICATOR : 46|6@0+ (1,0) [0|1] "" XXX
 SG_ FR_INDICATOR : 54|6@0+ (1,0) [0|63] "" XXX
 SG_ RIGHT_BLOCKED : 64|1@0+ (1,0) [0|1] "" XXX

BO_ 874 BLINDSPOTS_FRONT_CORNER_2: 16 XXX
 SG_ COUNTER : 16|8@1+ (1,0) [0|255] "" XXX
 SG_ CHECKSUM : 0|16@1+ (1,0) [0|65535] "" XXX

BO_ 485 BLINDSPOTS_FRONT_CORNER_1: 16 XXX
 SG_ COUNTER : 16|8@1+ (1,0) [0|255] "" XXX
 SG_ CHECKSUM : 0|16@1+ (1,0) [0|65535] "" XXX
 SG_ NEW_SIGNAL_1 : 108|2@0+ (1,0) [0|3] "" XXX
 SG_ NEW_SIGNAL_2 : 96|1@0+ (1,0) [0|1] "" XXX
 SG_ NEW_SIGNAL_3 : 88|1@0+ (1,0) [0|1] "" XXX
 SG_ NEW_SIGNAL_4 : 80|1@0+ (1,0) [0|1] "" XXX
 SG_ NEW_SIGNAL_5 : 31|2@0+ (1,0) [0|3] "" XXX
 SG_ REVERSING : 24|1@0+ (1,0) [0|1] "" XXX
 SG_ NEW_SIGNAL_7 : 32|2@1+ (1,0) [0|3] "" XXX
 SG_ NEW_SIGNAL_8 : 47|8@0+ (1,0) [0|255] "" XXX
 SG_ NEW_SIGNAL_9 : 55|8@0+ (1,0) [0|255] "" XXX

BO_ 506 CLUSTER_SPEED_LIMIT: 32 XXX
 SG_ SPEED_LIMIT_3 : 119|8@0+ (1,0) [0|255] "" XXX
 SG_ SPEED_LIMIT_2 : 47|7@0+ (1,0) [0|255] "" XXX
 SG_ SPEED_LIMIT_1 : 39|7@0+ (1,0) [0|255] "" XXX
 SG_ SPEED_CHANGE_BLINKING : 129|1@1+ (1,0) [0|3] "" XXX
 SG_ CHIME_2 : 122|2@1+ (1,0) [0|7] "" XXX
 SG_ CHIME_1 : 133|1@0+ (1,0) [0|1] "" XXX
 SG_ ARROW_DOWN : 120|1@0+ (1,0) [0|1] "" XXX
 SG_ ARROW_UP : 121|1@0+ (1,0) [0|1] "" XXX
 SG_ SECONDARY_LIMIT_1 : 79|8@0+ (1,0) [0|127] "" XXX
 SG_ SECONDARY_LIMIT_2 : 103|8@0+ (1,0) [0|127] "" XXX
 SG_ SCHOOL_ZONE : 155|1@0+ (1,0) [0|1] "" XXX

BO_ 1144 DRIVE_MODE: 8 XXX
 SG_ DRIVE_MODE : 0|16@1+ (1,-61611) [0|61611] "" XXX
 SG_ DRIVE_MODE2 : 28|3@1+ (1,0) [1|3] "" XXX

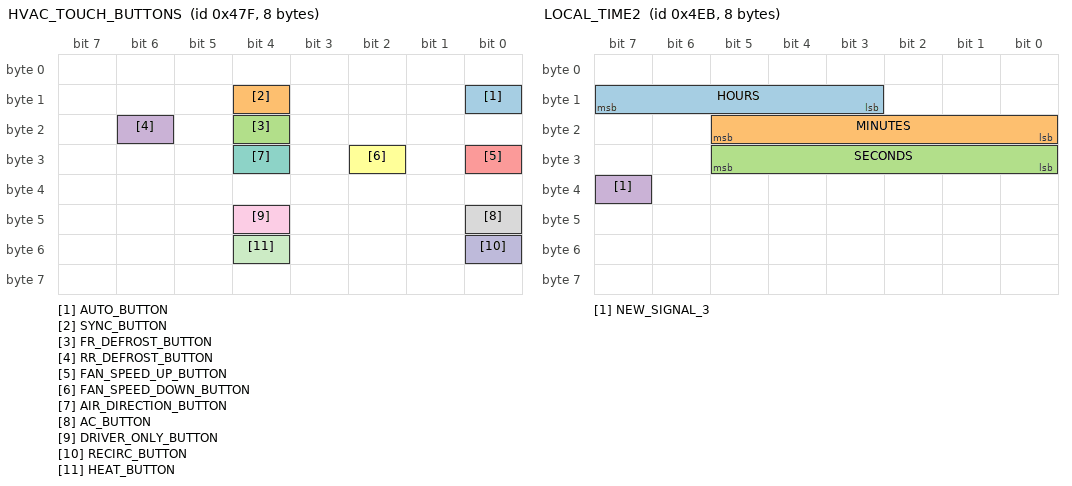
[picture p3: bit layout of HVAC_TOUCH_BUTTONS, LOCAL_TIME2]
BO_ 1151 HVAC_TOUCH_BUTTONS: 8 XXX
 SG_ AUTO_BUTTON : 8|1@0+ (1,0) [0|1] "" XXX
 SG_ SYNC_BUTTON : 12|1@0+ (1,0) [0|1] "" XXX
 SG_ FR_DEFROST_BUTTON : 20|1@0+ (1,0) [0|1] "" XXX
 SG_ RR_DEFROST_BUTTON : 22|1@0+ (1,0) [0|1] "" XXX
 SG_ FAN_SPEED_UP_BUTTON : 24|1@0+ (1,0) [0|1] "" XXX
 SG_ FAN_SPEED_DOWN_BUTTON : 26|1@0+ (1,0) [0|1] "" XXX
 SG_ AIR_DIRECTION_BUTTON : 28|1@0+ (1,0) [0|1] "" XXX
 SG_ AC_BUTTON : 40|1@0+ (1,0) [0|1] "" XXX
 SG_ DRIVER_ONLY_BUTTON : 44|1@0+ (1,0) [0|1] "" XXX
 SG_ RECIRC_BUTTON : 48|1@0+ (1,0) [0|1] "" XXX
 SG_ HEAT_BUTTON : 52|1@0+ (1,0) [0|1] "" XXX

BO_ 1259 LOCAL_TIME2: 8 XXX
 SG_ HOURS : 15|5@0+ (1,0) [0|31] "" XXX
 SG_ MINUTES : 21|6@0+ (1,0) [0|63] "" XXX
 SG_ SECONDS : 24|6@1+ (1,0) [0|63] "" XXX
 SG_ NEW_SIGNAL_3 : 39|1@0+ (1,0) [0|1] "" XXX

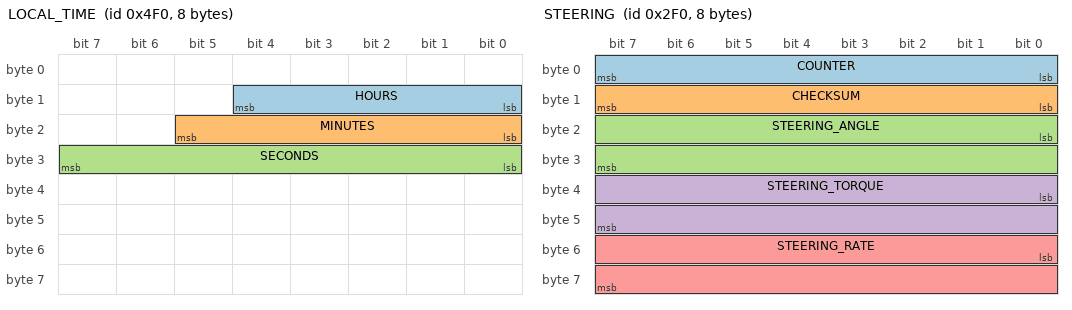
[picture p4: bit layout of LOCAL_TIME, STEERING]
BO_ 1264 LOCAL_TIME: 8 XXX
 SG_ HOURS : 12|5@0+ (1,0) [0|31] "" XXX
 SG_ MINUTES : 21|6@0+ (1,0) [0|63] "" XXX
 SG_ SECONDS : 31|8@0+ (1,0) [0|59] "" XXX

BO_ 928 TPMS: 16 XXX
 SG_ PRESSURE_FL : 39|8@0+ (1,0) [0|255] "" XXX
 SG_ PRESSURE_FR : 47|8@0+ (1,0) [0|255] "" XXX
 SG_ PRESSURE_RL : 55|8@0+ (1,0) [0|255] "" XXX
 SG_ PRESSURE_RR : 63|8@0+ (1,0) [0|255] "" XXX
 SG_ STATUS_TPMS : 66|3@0+ (1,0) [0|3] "" XXX
 SG_ UNIT : 68|2@0+ (1,0) [0|3] "" XXX

BO_ 256 VEHICLE_STATE: 24 XXX
 SG_ COUNTER                     : 0|8@1+  (1,0) [0|255] "" XXX
 SG_ CHECKSUM                    : 8|8@1+  (1,0) [0|255] "" XXX
 SG_ COUNTER2                    : 16|8@1+ (1,0) [0|255] "" XXX
 SG_ GEAR_SHIFTER                : 32|4@1+ (1,0) [0|15] "" XXX
 SG_ DOOR_FL                     : 72|1@1+ (1,0) [0|1] "" XXX
 SG_ DOOR_FR                     : 73|1@1+ (1,0) [0|1] "" XXX
 SG_ DOOR_RL                     : 74|1@1+ (1,0) [0|1] "" XXX
 SG_ DOOR_RR                     : 75|1@1+ (1,0) [0|1] "" XXX
 SG_ SEATBELT_DRIVER_LATCHED     : 76|1@1+ (1,0) [0|1] "" XXX
 SG_ PARKING_BRAKE               : 119|1@1+ (1,0) [0|1] "" XXX

BO_ 272 POWERTRAIN: 32 XXX
 SG_ COUNTER                     : 0|8@1+  (1,0) [0|255] "" XXX
 SG_ CHECKSUM                    : 8|8@1+  (1,0) [0|255] "" XXX
 SG_ COUNTER2                    : 16|8@1+ (1,0) [0|255] "" XXX
 SG_ LEFT_BLINKER                : 168|1@1+ (1,0) [0|1] "" XXX
 SG_ RIGHT_BLINKER               : 169|1@1+ (1,0) [0|1] "" XXX
 SG_ REGEN_LEVEL                 : 176|4@1+ (1,0) [0|3] "" XXX

BO_ 357 BRAKE_ACCEL: 16 XXX
 SG_ COUNTER                     : 0|8@1+  (1,0) [0|255] "" XXX
 SG_ CHECKSUM                    : 8|8@1+  (1,0) [0|255] "" XXX
 SG_ COUNTER2                    : 16|8@1+ (1,0) [0|255] "" XXX
 SG_ BRAKE_PRESSURE              : 24|8@1+ (1,0) [0|255] "" XXX
 SG_ GAS_PEDAL                   : 40|8@1+ (1,0) [0|255] "" XXX

BO_ 752 STEERING: 8 XXX
 SG_ COUNTER                     : 0|8@1+   (1,0) [0|255] "" XXX
 SG_ CHECKSUM                    : 8|8@1+   (1,0) [0|255] "" XXX
 SG_ STEERING_ANGLE              : 16|16@1- (0.1,0) [-450|450] "deg" XXX
 SG_ STEERING_TORQUE             : 32|16@1- (0.1,0) [-50|50] "Nm" XXX
 SG_ STEERING_RATE               : 48|16@1- (0.1,0) [-500|500] "deg/s" XXX

BO_ 864 WHEEL_SPEEDS_FL_RL: 32 XXX
 SG_ COUNTER                     : 0|8@1+  (1,0) [0|255] "" XXX
 SG_ CHECKSUM                    : 8|8@1+  (1,0) [0|255] "" XXX
 SG_ COUNTER2                    : 16|8@1+ (1,0) [0|255] "" XXX
 SG_ WHEEL_SPEED_FL              : 0|16@1+ (0.03125,0) [0|250] "kph" XXX
 SG_ WHEEL_SPEED_RL              : 16|16@1+ (0.03125,0) [0|250] "kph" XXX

BO_ 865 WHEEL_SPEEDS_FR_RR: 32 XXX
 SG_ COUNTER                     : 0|8@1+  (1,0) [0|255] "" XXX
 SG_ CHECKSUM                    : 8|8@1+  (1,0) [0|255] "" XXX
 SG_ COUNTER2                    : 16|8@1+ (1,0) [0|255] "" XXX
 SG_ WHEEL_SPEED_FR              : 0|16@1+ (0.03125,0) [0|250] "kph" XXX
 SG_ WHEEL_SPEED_RR              : 16|16@1+ (0.03125,0) [0|250] "kph" XXX

BO_ 896 TCS_ESC: 24 XXX
 SG_ COUNTER                     : 0|8@1+  (1,0) [0|255] "" XXX
 SG_ CHECKSUM                    : 8|8@1+  (1,0) [0|255] "" XXX
 SG_ COUNTER2                    : 16|8@1+ (1,0) [0|255] "" XXX
 SG_ ESP_DISABLED                : 24|1@1+ (1,0) [0|1] "" XXX
 SG_ ESP_ACTIVE                  : 25|1@1+ (1,0) [0|1] "" XXX
 SG_ TRACTION_CONTROL            : 26|1@1+ (1,0) [0|1] "" XXX
 SG_ ABS_ACTIVE                  : 27|1@1+ (1,0) [0|1] "" XXX

BO_ 917 STEERING_FD: 32 XXX
 SG_ STEER_FD_RAW_BYTE0         : 0|8@1+  (1,0) [0|255] "" XXX
 SG_ STEER_FD_RAW_BYTE1         : 8|8@1+  (1,0) [0|255] "" XXX
 SG_ STEER_FD_RAW_BYTE2         : 16|8@1+ (1,0) [0|255] "" XXX
 SG_ STEER_FD_STATUS_BYTE9      : 72|8@1+ (1,0) [0|255] "" XXX
 SG_ STEER_FD_STATUS_BYTE10     : 80|8@1+ (1,0) [0|255] "" XXX
 SG_ STEER_FD_STATUS_BYTE11     : 88|8@1+ (1,0) [0|255] "" XXX

BO_ 933 SCC_CONTROL: 24 XXX
 SG_ COUNTER                     : 0|8@1+  (1,0) [0|255] "" XXX
 SG_ CHECKSUM                    : 8|8@1+  (1,0) [0|255] "" XXX
 SG_ COUNTER2                    : 16|8@1+ (1,0) [0|255] "" XXX
 SG_ CRUISE_ACTIVE               : 24|1@1+ (1,0) [0|1] "" XXX
 SG_ CRUISE_STANDSTILL           : 25|1@1+ (1,0) [0|1] "" XXX
 SG_ CRUISE_AVAILABLE            : 26|1@1+ (1,0) [0|1] "" XXX
 SG_ SET_SPEED                   : 32|8@1+ (1,0) [0|255] "kph" XXX
 SG_ LEAD_DISTANCE               : 40|8@1+ (1,0) [0|255] "m" XXX
 SG_ LEAD_SPEED                  : 48|16@1- (0.1,0) [-200|200] "kph" XXX

BO_ 934 LKAS_1: 24 XXX
 SG_ COUNTER                     : 0|8@1+  (1,0) [0|255] "" XXX
 SG_ CHECKSUM                    : 8|8@1+  (1,0) [0|255] "" XXX
 SG_ COUNTER2                    : 16|8@1+ (1,0) [0|255] "" XXX
 SG_ LFA_ACTIVE                  : 24|1@1+ (1,0) [0|1] "" XXX
 SG_ LFA_AVAILABLE               : 25|1@1+ (1,0) [0|1] "" XXX
 SG_ LANE_DISTANCE_LEFT          : 32|8@1+ (0.01,0) [0|2.55] "m" XXX
 SG_ LANE_DISTANCE_RIGHT         : 40|8@1+ (0.01,0) [0|2.55] "m" XXX

BO_ 935 LKAS_2: 24 XXX
 SG_ COUNTER                     : 0|8@1+  (1,0) [0|255] "" XXX
 SG_ CHECKSUM                    : 8|8@1+  (1,0) [0|255] "" XXX
 SG_ COUNTER2                    : 16|8@1+ (1,0) [0|255] "" XXX
 SG_ LANE_DETECTED               : 24|1@1+ (1,0) [0|1] "" XXX
 SG_ LEFT_LANE_DETECTED          : 25|1@1+ (1,0) [0|1] "" XXX
 SG_ RIGHT_LANE_DETECTED         : 26|1@1+ (1,0) [0|1] "" XXX

BO_ 976 ADAS_1: 32 XXX
 SG_ COUNTER                     : 0|8@1+  (1,0) [0|255] "" XXX
 SG_ CHECKSUM                    : 8|8@1+  (1,0) [0|255] "" XXX
 SG_ COUNTER2                    : 16|8@1+ (1,0) [0|255] "" XXX
 SG_ ADAS_ENABLED                : 24|1@1+ (1,0) [0|1] "" XXX

BO_ 977 ADAS_2: 32 XXX
 SG_ COUNTER                     : 0|8@1+  (1,0) [0|255] "" XXX
 SG_ CHECKSUM                    : 8|8@1+  (1,0) [0|255] "" XXX
 SG_ COUNTER2                    : 16|8@1+ (1,0) [0|255] "" XXX

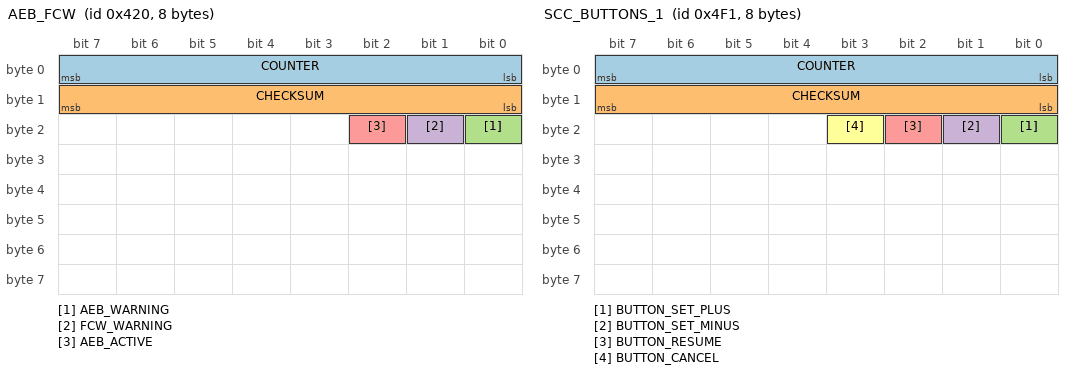
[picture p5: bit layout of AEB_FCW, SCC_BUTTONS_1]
BO_ 1056 AEB_FCW: 8 XXX
 SG_ COUNTER                     : 0|8@1+  (1,0) [0|255] "" XXX
 SG_ CHECKSUM                    : 8|8@1+  (1,0) [0|255] "" XXX
 SG_ AEB_WARNING                 : 16|1@1+ (1,0) [0|1] "" XXX
 SG_ FCW_WARNING                 : 17|1@1+ (1,0) [0|1] "" XXX
 SG_ AEB_ACTIVE                  : 18|1@1+ (1,0) [0|1] "" XXX

BO_ 1265 SCC_BUTTONS_1: 8 XXX
 SG_ COUNTER                     : 0|8@1+  (1,0) [0|255] "" XXX
 SG_ CHECKSUM                    : 8|8@1+  (1,0) [0|255] "" XXX
 SG_ BUTTON_SET_PLUS             : 16|1@1+ (1,0) [0|1] "" XXX
 SG_ BUTTON_SET_MINUS            : 17|1@1+ (1,0) [0|1] "" XXX
 SG_ BUTTON_RESUME               : 18|1@1+ (1,0) [0|1] "" XXX
 SG_ BUTTON_CANCEL               : 19|1@1+ (1,0) [0|1] "" XXX

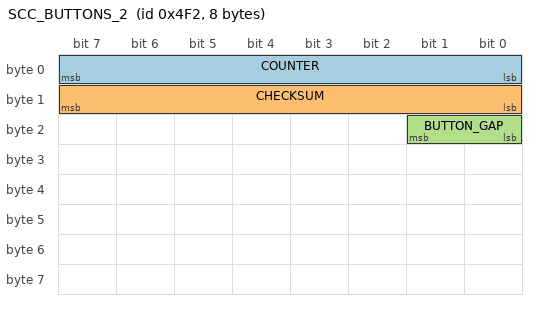
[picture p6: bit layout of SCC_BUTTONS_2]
BO_ 1266 SCC_BUTTONS_2: 8 XXX
 SG_ COUNTER                     : 0|8@1+  (1,0) [0|255] "" XXX
 SG_ CHECKSUM                    : 8|8@1+  (1,0) [0|255] "" XXX
 SG_ BUTTON_GAP                  : 16|2@1+ (1,0) [0|3] "" XXX

CM_ BO_ 256 "Vehicle state including gear, doors, seatbelt - Confirmed: Gear P/R/N/D";
CM_ BO_ 272 "Powertrain state including turn signals - Status: Turn signals unconfirmed";
CM_ BO_ 357 "Brake and accelerator pedal positions - Status: Gas pedal unconfirmed";
CM_ BO_ 752 "Steering wheel angle and torque (classic CAN) - PARTIAL: Needs validation vs CAN-FD";
CM_ BO_ 864 "Wheel speeds front left and rear left - Confirmed (from base platform)";
CM_ BO_ 865 "Wheel speeds front right and rear right - Confirmed (from base platform)";
CM_ BO_ 896 "TCS and ESC status - Confirmed (from base platform)";
CM_ BO_ 917 "EV4 Steering CAN-FD frame - drive4 정지+핸들락 테스트에서 bytes0-2가 조향에 따라 가장 크게 변화";
CM_ BO_ 933 "Smart Cruise Control status - Confirmed";
CM_ BO_ 934 "Lane Following Assist status 1 - Confirmed";
CM_ BO_ 935 "Lane Following Assist status 2 - Confirmed";
CM_ BO_ 976 "ADAS system 1 - Confirmed";
CM_ BO_ 977 "ADAS system 2 - Confirmed";
CM_ BO_ 1056 "AEB and FCW warnings - Confirmed";
CM_ BO_ 1265 "SCC buttons 1 - Status: Unconfirmed";
CM_ BO_ 1266 "SCC buttons 2 - Status: Unconfirmed";

CM_ SG_ 256 GEAR_SHIFTER              "Gear shifter position - CONFIRMED: 0=N, 1=R, 3=D, 5=P";
CM_ SG_ 752 STEERING_ANGLE            "Steering wheel angle - PARTIAL: classic CAN, needs CAN-FD cross-check";
CM_ SG_ 752 STEERING_TORQUE           "Driver steering torque - PARTIAL: Needs scale validation";
CM_ SG_ 272 LEFT_BLINKER              "Left turn signal - UNCONFIRMED: Needs testing";
CM_ SG_ 272 RIGHT_BLINKER             "Right turn signal - UNCONFIRMED: Needs testing";
CM_ SG_ 357 GAS_PEDAL                 "Accelerator pedal position - UNCONFIRMED: Needs testing";
CM_ SG_ 256 DOOR_FL                   "Front left door - UNCONFIRMED: Needs testing";
CM_ SG_ 256 DOOR_FR                   "Front right door - UNCONFIRMED: Needs testing";
CM_ SG_ 256 DOOR_RL                   "Rear left door - UNCONFIRMED: Needs testing";
CM_ SG_ 256 DOOR_RR                   "Rear right door - UNCONFIRMED: Needs testing";
CM_ SG_ 256 SEATBELT_DRIVER_LATCHED   "Driver seatbelt latched - UNCONFIRMED: Needs testing";
CM_ SG_ 256 PARKING_BRAKE             "Electronic parking brake - UNCONFIRMED: Needs testing";

VAL_ 256 GEAR_SHIFTER           0 "neutral" 1 "reverse" 3 "drive" 5 "park" ;
VAL_ 272 LEFT_BLINKER           0 "off" 1 "on" ;
VAL_ 272 RIGHT_BLINKER          0 "off" 1 "on" ;
VAL_ 256 DOOR_FL                0 "closed" 1 "open" ;
VAL_ 256 DOOR_FR                0 "closed" 1 "open" ;
VAL_ 256 DOOR_RL                0 "closed" 1 "open" ;
VAL_ 256 DOOR_RR                0 "closed" 1 "open" ;
VAL_ 256 SEATBELT_DRIVER_LATCHED 0 "unlatched" 1 "latched" ;
VAL_ 256 PARKING_BRAKE          0 "released" 1 "engaged" ;
VAL_ 896 ESP_DISABLED           0 "enabled" 1 "disabled" ;
VAL_ 896 ESP_ACTIVE             0 "inactive" 1 "active" ;
VAL_ 933 CRUISE_ACTIVE          0 "inactive" 1 "active" ;
VAL_ 933 CRUISE_STANDSTILL      0 "moving" 1 "standstill" ;
VAL_ 933 CRUISE_AVAILABLE       0 "unavailable" 1 "available" ;
VAL_ 934 LFA_ACTIVE             0 "inactive" 1 "active" ;
VAL_ 934 LFA_AVAILABLE          0 "unavailable" 1 "available" ;
VAL_ 1056 AEB_WARNING           0 "off" 1 "warning" ;
VAL_ 1056 FCW_WARNING           0 "off" 1 "warning" ;
VAL_ 1056 AEB_ACTIVE            0 "inactive" 1 "active" ;

CM_ 272 "Alternative LKAS message, used on cars such as 2023 Ioniq 6, 2nd gen Kona. Matches LKAS except size is 32 bytes";
CM_ 676 "Contains signals with detailed lane line information. Used by ADAS ECU on HDA 2 vehicles to operate LFA.";
CM_ 866 "Contains signals with detailed lane line information. Used by ADAS ECU on HDA 2 vehicles to operate LFA. Used on cars that use message 272.";
CM_ 1043 "Lamp signals do not seem universal on cars that use LKAS_ALT, but stalk signals do.";

CM_ SG_ 80 HAS_LANE_SAFETY "If 0, hides LKAS 'Lane Safety' menu from vehicle settings";
CM_ SG_ 96 BRAKE_PRESSURE "User applied brake pedal pressure. Ramps from computer applied pressure on falling edge of cruise. Cruise cancels if !=0";
CM_ SG_ 101 BRAKE_POSITION "User applied brake pedal position, max is ~700. Signed on some vehicles";
CM_ SG_ 373 PROBABLY_EQUIP "aeb equip?";
CM_ SG_ 373 ACCEnable "Likely a copy of CAN's TCS13->ACCEnable";
CM_ SG_ 373 DriverBraking "Likely derived from BRAKE->BRAKE_POSITION";
CM_ SG_ 373 DriverBrakingLowSens "Higher threshold version of DriverBraking";
CM_ SG_ 352 SET_ME_9 "has something to do with AEB settings";
CM_ SG_ 416 VSetDis "set speed in display units";
CM_ SG_ 676 LEFT_LANE_LINE "Left lane line confidence";
CM_ SG_ 676 RIGHT_LANE_LINE "Right lane line confidence";
CM_ SG_ 736 MAX_SPEED "Display units. Restricts car from driving above this speed unless accelerator pedal is depressed beyond pressure point";
CM_ SG_ 866 LEFT_LANE_LINE "Left lane line confidence";
CM_ SG_ 866 RIGHT_LANE_LINE "Right lane line confidence";
CM_ SG_ 961 COUNTER_ALT "only increments on change";
CM_ SG_ 1041 COUNTER_ALT "only increments on change";
CM_ SG_ 1043 COUNTER_ALT "only increments on change";
CM_ SG_ 1043 USE_ALT_LAMP "likely 1 on cars that use alt lamp signals";
VAL_ 53 GEAR 0 "P" 5 "D" 6 "N" 7 "R" ;
VAL_ 64 GEAR 0 "P" 5 "D" 6 "N" 7 "R" ;
VAL_ 69 GEAR 0 "P" 5 "D" 6 "N" 7 "R" ;
VAL_ 112 GEAR 0 "P" 5 "D" 6 "N" 7 "R" ;
VAL_ 80 LKA_ICON 0 "hidden" 1 "grey" 2 "green" 3 "flashing green" ;
VAL_ 80 LKA_MODE 1 "warning only" 2 "assist" 6 "off" ;
VAL_ 96 TRACTION_AND_STABILITY_CONTROL 0 "On" 5 "Limited" 1 "Off";
VAL_ 234 LKA_FAULT 0 "ok" 1 "lka fault" ;
VAL_ 272 LKA_ICON 0 "hidden" 1 "grey" 2 "green" 3 "flashing green" ;
VAL_ 272 LKA_MODE 1 "warning only" 2 "assist" 6 "off" ;
VAL_ 298 LKA_ICON 0 "hidden" 1 "grey" 2 "green" 3 "flashing green" ;
VAL_ 298 LKA_MODE 1 "warning only" 2 "assist" 6 "off" ;
VAL_ 304 PARK_BUTTON 1 "Pressed" 2 "Not Pressed";
VAL_ 304 KNOB_POSITION 1 "R" 2 "N (on R side)" 3 "Centered" 4 "N (on D side)" 5 "D";
VAL_ 304 GEAR 1 "P" 2 "R" 3 "N" 4 "D" ;
VAL_ 352 AEB_SETTING 1 "off" 2 "warning only" 3 "active assist" ;
VAL_ 362 BLINKER_CONTROL 1 "hazards" 2 "hazards button backlight" 3 "left blinkers" 4 "right blinkers";
VAL_ 373 ACCEnable 0 "SCC ready" 1 "SCC temp fault" 2 "SCC permanent fault" 3 "SCC permanent fault, communication issue";
VAL_ 416 ACCMode 0 "off" 1 "enabled" 2 "driver_override" 3 "off_maybe_fault" 4 "cancelled" ;
VAL_ 426 CRUISE_BUTTONS 0 "none" 1 "res_accel" 2 "set_decel" 3 "gap_distance" 4 "pause_resume" ;
VAL_ 463 CRUISE_BUTTONS 0 "none" 1 "res_accel" 2 "set_decel" 3 "gap_distance" 4 "pause_resume" ;
VAL_ 463 RIGHT_PADDLE 0 "Not Pulled" 1 "Pulled";
VAL_ 463 LEFT_PADDLE 0 "Not Pulled" 1 "Pulled";
VAL_ 676 LEFT_LANE_LINE 0 "Not Detected" 1 "Low Confidence" 2 "Medium Confidence" 3 "High Confidence";
VAL_ 676 RIGHT_LANE_LINE 0 "Not Detected" 1 "Low Confidence" 2 "Medium Confidence" 3 "High Confidence";
VAL_ 736 MSLA_STATUS 0 "disabled" 1 "active" 2 "paused";
VAL_ 866 LEFT_LANE_LINE 0 "Not Detected" 1 "Low Confidence" 2 "Medium Confidence" 3 "High Confidence";
VAL_ 866 RIGHT_LANE_LINE 0 "Not Detected" 1 "Low Confidence" 2 "Medium Confidence" 3 "High Confidence";
VAL_ 1041 DRIVER_DOOR 0 "Closed" 1 "Opened";
VAL_ 1041 PASSENGER_DOOR 0 "Closed" 1 "Opened";
VAL_ 1041 DRIVER_REAR_DOOR 0 "Closed" 1 "Opened";
VAL_ 1041 PASSENGER_REAR_DOOR 0 "Closed" 1 "Opened";
VAL_ 1041 DRIVER_SEATBELT 0 "Unlatched" 1 "Latched";
VAL_ 1041 PASSENGER_SEATBELT 0 "Unlatched" 1 "Latched";
VAL_ 1144 DRIVE_MODE2 3 "Set Sport" 1 "Set Normal" 2 "Set Eco";
VAL_ 1240 DISTANCE_UNIT 1 "Miles" 0 "Kilometers";
